# va416xx register map
Vendor: VORAGO TECHNOLOGIES; Series: M4; File version: 1.3
CPU: CM4 r0p1, little endian, no MPU, FPU, 4 interrupt priority bits
Registers are 32-bit, read-write, reset 0x0 unless marked. A register's access mark holds for its fields unless they carry their own. Offsets are from the block's base; [hi:lo] are bit positions; 'fields as' and 'values as' point back to an identical list.

## I2C0 — I2C Peripheral
Base 0x40016000
Same registers: I2C1 0x40016400, I2C2 0x40016800
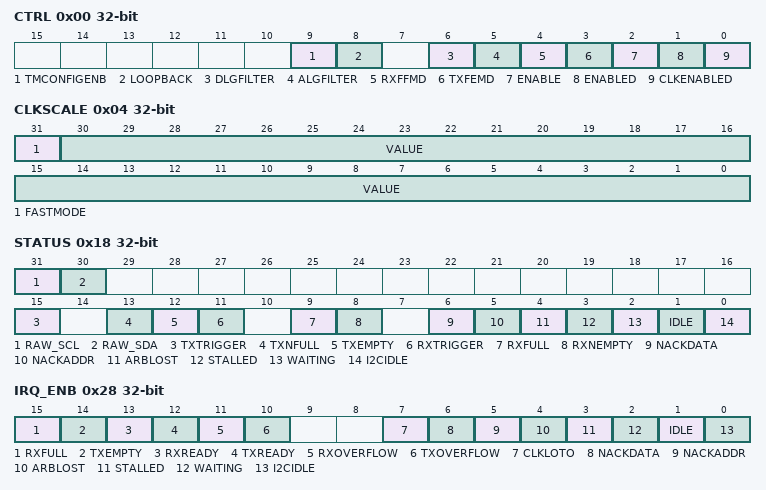
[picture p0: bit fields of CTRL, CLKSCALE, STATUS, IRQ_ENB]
0x00 CTRL — Control Register
  [9] TMCONFIGENB — Enable Timing Config Register
  [8] LOOPBACK — Enable LoopBack Mode
  [6] DLGFILTER — Enable Input Digital Glitch Filter
  [5] ALGFILTER — Enable Input Analog Glitch Filter
  [4] RXFFMD — RX FIFO Full Mode
  [3] TXFEMD — TX FIFIO Empty Mode
  [2] ENABLE — I2C Active
  [1] ENABLED — I2C Activated
  [0] CLKENABLED — I2C CLK Enabled
0x04 CLKSCALE — Clock Scale divide value
  [31] FASTMODE — Enable FastMode
  [30:0] VALUE — Enable FastMode
0x08 WORDS — Word Count value
0x0C ADDRESS — I2C Address value
0x10 DATA — Data Input/Output
0x14 CMD — Command Register
0x18 STATUS — I2C Controller Status Register
  [31] RAW_SCL — I2C Raw SCL value
  [30] RAW_SDA — I2C Raw SDA value
  [15] TXTRIGGER — TX FIFO Below Trigger Level
  [13] TXNFULL — TX FIFO is Full
  [12] TXEMPTY — TX FIFO is Empty
  [11] RXTRIGGER — RX FIFO Above Trigger Level
  [9] RXFULL — RX FIFO is Full
  [8] RXNEMPTY — RX FIFO is Not Empty
  [6] NACKDATA — I2C Data was not Acknowledged
  [5] NACKADDR — I2C Address was not Acknowledged
  [4] ARBLOST — I2C Arbitration was lost
  [3] STALLED — Controller is Stalled
  [2] WAITING — Controller is Waiting
  [1] IDLE — I2C controller is Idle
  [0] I2CIDLE — I2C bus is idle
0x1C STATE ro — Internal STATE of I2C Master Controller
0x20 TXCOUNT ro
0x24 RXCOUNT ro
0x28 IRQ_ENB — Interrupt Enable Register
  [15] RXFULL — RX FIFO Full
  [14] TXEMPTY — TX FIFO Empty
  [13] RXREADY — RX FIFO Ready
  [12] TXREADY — TX FIFO Ready
  [11] RXOVERFLOW — TX FIFO Overflowed
  [10] TXOVERFLOW — TX FIFO Overflowed
  [7] CLKLOTO — I2C Clock Low Timeout
  [6] NACKDATA — I2C Data was not Acknowledged
  [5] NACKADDR — I2C Address was not Acknowledged
  [4] ARBLOST — I2C Arbitration was lost
  [3] STALLED — Controller is Stalled
  [2] WAITING — Controller is Waiting
  [1] IDLE — Controller is Idle
  [0] I2CIDLE — I2C Bus is Idle
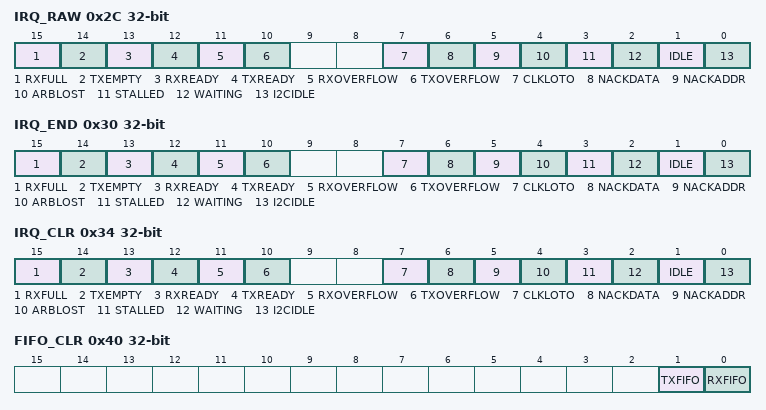
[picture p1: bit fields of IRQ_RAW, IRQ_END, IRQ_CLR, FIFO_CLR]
0x2C IRQ_RAW ro — Raw Interrupt Status Register
  fields as IRQ_ENB
0x30 IRQ_END ro — Enabled Interrupt Status Register
  fields as IRQ_ENB
0x34 IRQ_CLR wo write-1-clears — Clear Interrupt Status Register
  fields as IRQ_ENB
0x38 RXFIFOIRQTRG — Rx FIFO IRQ Trigger Level
0x3C TXFIFOIRQTRG — Tx FIFO IRQ Trigger Level
0x40 FIFO_CLR wo — Clear FIFO Register
  [1] TXFIFO — Clear Tx FIFO
  [0] RXFIFO — Clear Rx FIFO
0x44 TMCONFIG — Timing Config Register
0x48 CLKTOLIMIT — Clock Low Timeout Limit Register
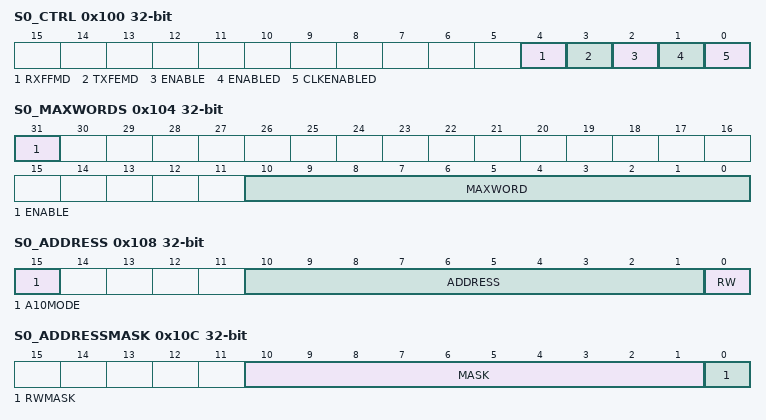
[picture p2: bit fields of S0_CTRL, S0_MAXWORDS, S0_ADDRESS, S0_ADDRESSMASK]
0x100 S0_CTRL — Slave Control Register
  [4] RXFFMD — RX FIFO Full Mode
  [3] TXFEMD — TX FIFIO Empty Mode
  [2] ENABLE — I2C Active
  [1] ENABLED — I2C Activated
  [0] CLKENABLED — I2C Enabled
0x104 S0_MAXWORDS — Slave MaxWords Register
  [31] ENABLE — Enables the max word count
  [10:0] MAXWORD — Max Word Count
0x108 S0_ADDRESS — Slave I2C Address Value
  [15] A10MODE — Enable 10b address mode
  [10:1] ADDRESS — Address value
  [0] RW — Read/Write value
0x10C S0_ADDRESSMASK — Slave I2C Address Mask value
  [10:1] MASK — Address mask value
  [0] RWMASK — Read/Write mask
0x110 S0_DATA — Slave Data Input/Output
  [7:0] VALUE — I2C data value
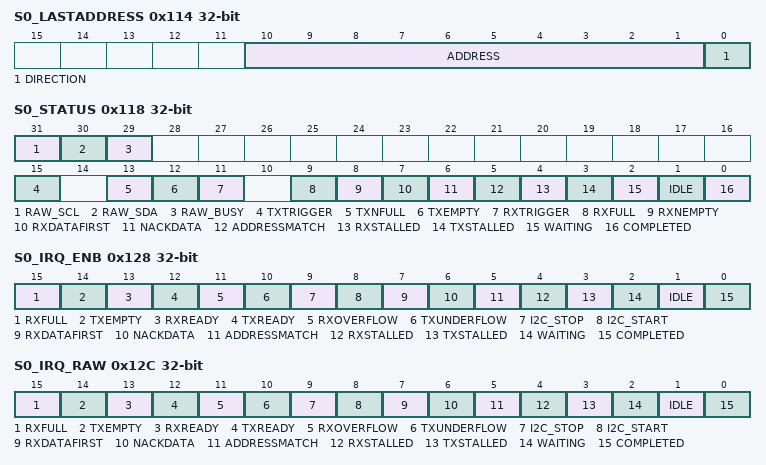
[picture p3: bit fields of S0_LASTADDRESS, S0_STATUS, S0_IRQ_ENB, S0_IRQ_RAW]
0x114 S0_LASTADDRESS ro — Slave I2C Last Address value
  [10:1] ADDRESS — Address value
  [0] DIRECTION — Transaction direction 0=master send, 1=master receive
0x118 S0_STATUS ro — Slave I2C Controller Status Register
  [31] RAW_SCL — I2C Raw SCL value
  [30] RAW_SDA — I2C Raw SDA value
  [29] RAW_BUSY — I2C Raw Busy value
  [15] TXTRIGGER — TX FIFO Below Trigger Level
  [13] TXNFULL — TX FIFO is Full
  [12] TXEMPTY — TX FIFO is Empty
  [11] RXTRIGGER — RX FIFO Above Trigger Level
  [9] RXFULL — RX FIFO is Full
  [8] RXNEMPTY — RX FIFO is Not Empty
  [7] RXDATAFIRST — Pending Data is first Byte following Address
  [6] NACKDATA — I2C Data was not Acknowledged
  [5] ADDRESSMATCH — I2C Address Match
  [4] RXSTALLED — Controller is Rx Stalled
  [3] TXSTALLED — Controller is Tx Stalled
  [2] WAITING — Controller is Waiting
  [1] IDLE — Controller is Idle
  [0] COMPLETED — Controller Complted a Transaction
0x11C S0_STATE ro — Internal STATE of I2C Slave Controller
0x120 S0_TXCOUNT ro — Slave TX Count Register
  [10:0] VALUE — Count value
0x124 S0_RXCOUNT ro — Slave RX Count Register
  [10:0] VALUE — Count value
0x128 S0_IRQ_ENB — Slave Interrupt Enable Register
  [15] RXFULL — RX FIFO Full
  [14] TXEMPTY — TX FIFO Empty
  [13] RXREADY — RX FIFO Ready
  [12] TXREADY — TX FIFO Ready
  [11] RXOVERFLOW — TX FIFO Overflowed
  [10] TXUNDERFLOW — TX FIFO Underflowed
  [9] I2C_STOP — I2C Stop Condition
  [8] I2C_START — I2C Start Condition
  [7] RXDATAFIRST — Pending Data is first Byte following Address
  [6] NACKDATA — I2C Data was not Acknowledged
  [5] ADDRESSMATCH — I2C Address Match
  [4] RXSTALLED — Controller is Rx Stalled
  [3] TXSTALLED — Controller is Tx Stalled
  [2] WAITING — Controller is Waiting
  [1] IDLE — Controller is Idle
  [0] COMPLETED — Controller Complted a Transaction
0x12C S0_IRQ_RAW ro — Slave Raw Interrupt Status Register
  fields as S0_IRQ_ENB
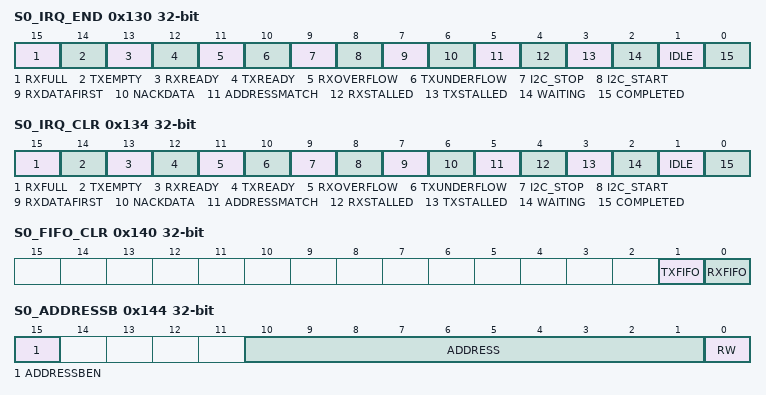
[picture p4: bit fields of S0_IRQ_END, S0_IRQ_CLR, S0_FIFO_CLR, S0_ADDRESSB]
0x130 S0_IRQ_END ro — Slave Enabled Interrupt Status Register
  fields as S0_IRQ_ENB
0x134 S0_IRQ_CLR wo write-1-clears — Slave Clear Interrupt Status Register
  fields as S0_IRQ_ENB
0x138 S0_RXFIFOIRQTRG — Slave Rx FIFO IRQ Trigger Level
  [4:0] LEVEL — Half full level for the Rx FIFO
0x13C S0_TXFIFOIRQTRG reset 0x8 — Slave Tx FIFO IRQ Trigger Level
  [4:0] LEVEL — Half full level for the Rx FIFO
0x140 S0_FIFO_CLR wo — Slave Clear FIFO Register
  [1] TXFIFO — Clear Tx FIFO
  [0] RXFIFO — Clear Rx FIFO
0x144 S0_ADDRESSB — Slave I2C Address B Value
  [15] ADDRESSBEN — Enable Address B
  [10:1] ADDRESS — Address value
  [0] RW — Read write value
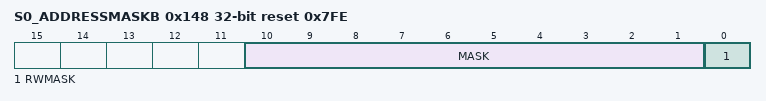
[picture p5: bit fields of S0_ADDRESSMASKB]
0x148 S0_ADDRESSMASKB reset 0x7FE — Slave I2C Address B Mask value
  [10:1] MASK — Address mask value
  [0] RWMASK — Read write mask
0x3FC PERID ro reset 0x21407E9 — Peripheral ID Register
